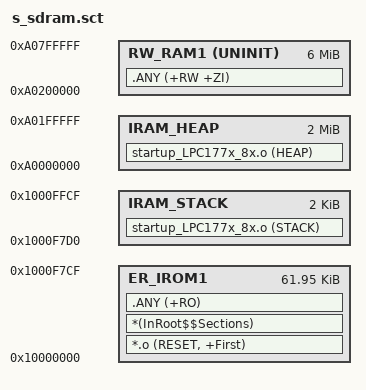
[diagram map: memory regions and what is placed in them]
; *************************************************************
; *** Scatter-Loading Description File generated by uVision ***
; *************************************************************

LR_IROM1 0x10000000  {    ; load region size_region
  ;ER_IROM1 0x00000000 0x00080000  {  ; load address = execution address
  ; *.o (RESET, +First)
  ; *(InRoot$$Sections)
  ; .ANY (+RO)
  ;}
  ER_IROM1 0x10000000 0xF7D0  {  ; load address = execution address
   *.o (RESET, +First)
   *(InRoot$$Sections)
   .ANY (+RO)
  }
  
  IRAM_STACK 0x1000F7D0 0x800 {  ; RW data
    startup_LPC177x_8x.o (STACK)
    
  }
  
  IRAM_HEAP 0xA0000000 0x0200000 {  ; RW data
    startup_LPC177x_8x.o (HEAP)
  }  
  
  RW_RAM1 0xA0200000 UNINIT 0x600000  {  ; RW data
   .ANY (+RW +ZI)

  }
  ;RW_IRAM1 0x10000000 0x00010000  {
   ;.ANY (+RW +ZI)
  ;}
  
  ;RW_STACK_RES 0x1000F7D0 EMPTY 0x800  ; Stack region 
  ;{
	;.(STACK)
  ;}

	
}
 
